# DEBUGSS_WRAP_ROM_TABLE_0_0_000700000000h register map
Vendor: Texas Instruments
Peripheral module from a debugger description file (folder am62D).
Registers are 32-bit, read-only, reset values left out (the file's numbers can be read two ways) unless marked. A register's access mark holds for its fields unless they carry their own. Offsets are as the file gives them; lines under a group give offsets from that group; [hi:lo] are bit positions; {n}, {i} and the like mark numbered series; 'fields as' and 'values as' point back to an identical list; <NAME> marks a mode.

## rom_table_0_0
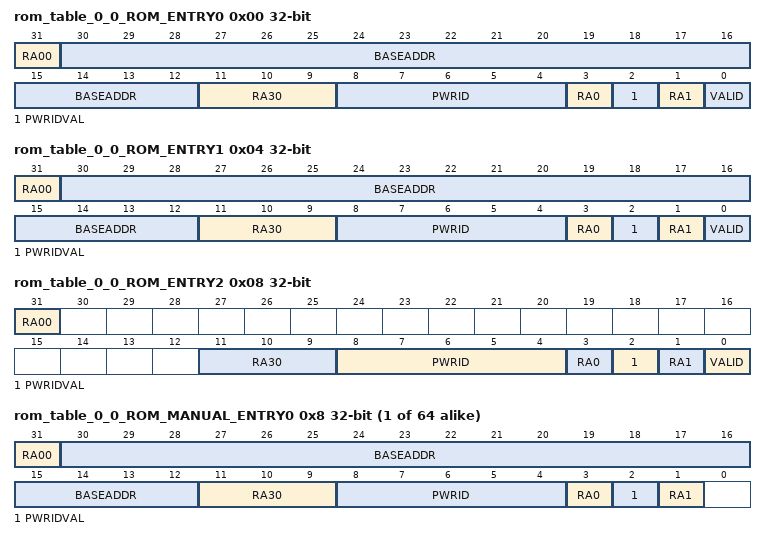
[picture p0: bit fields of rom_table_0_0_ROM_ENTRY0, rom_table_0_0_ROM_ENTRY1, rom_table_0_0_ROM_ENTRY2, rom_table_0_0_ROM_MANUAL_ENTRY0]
0x00 rom_table_0_0_ROM_ENTRY0
  [31] RA00 — always read as 0
  [30:12] BASEADDR — Component base address
  [11:9] RA30 — always read as 0
  [8:4] PWRID — always read as 0
  [3] RA0 — always read as 0
  [2] PWRIDVAL — power id valid
  [1] RA1 — always read as 1
  [0] VALID — Component present,1, or not present,0, status bit
0x04 rom_table_0_0_ROM_ENTRY1
  fields as rom_table_0_0_ROM_ENTRY0
0x08 rom_table_0_0_ROM_ENTRY2
  [31] RA00 — always read as 0
  [11:9] RA30 — always read as 0
  [8:4] PWRID — always read as 0
  [3] RA0 — always read as 0
  [2] PWRIDVAL — power id valid
  [1] RA1 — always read as 1
  [0] VALID — Component present,1, or not present,0, status bit
{0x8+4i} rom_table_0_0_ROM_MANUAL_ENTRY{i} (i=0..63)
  [31] RA00 — always read as 0
  [30:12] BASEADDR — Component base address
  [11:9] RA30 — always read as 0
  [8:4] PWRID — always read as 0
  [3] RA0 — always read as 0
  [2] PWRIDVAL — power id valid
  [1] RA1 — always read as 1
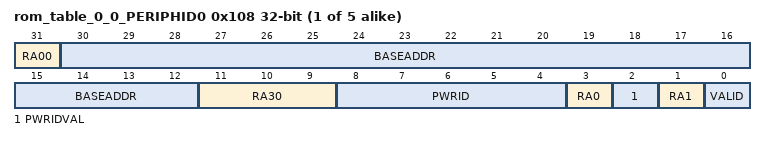
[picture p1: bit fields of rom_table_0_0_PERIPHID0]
{0x108+4i} rom_table_0_0_PERIPHID{i} (i=0..4)
  fields as rom_table_0_0_ROM_ENTRY0
0x3FC rom_table_0_0_COMPID{i} (i=0..3)
  [31:0] VAR — Component id{i}
